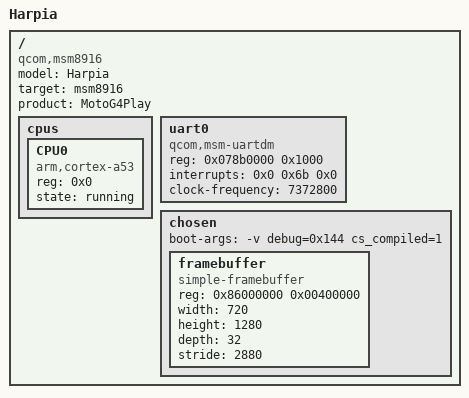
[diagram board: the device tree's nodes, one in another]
/ {
    model = "Harpia";
    target = "msm8916";
    product = "MotoG4Play";
    compatible = "qcom,msm8916";
    #adress-cells = <1>;
    #size-cells = <1>;

    cpus {
        #adress-cells = <1>;
        #size-cells = <0>;

        CPU0 {
            device_type = "cpu";
            compatible = "arm,cortex-a53";
            reg = <0x0>;
            state = "running";
        };
    };

    uart0 {
        device_type = "uart";
        compatible = "qcom,msm-uartdm";
        reg = <0x078b0000 0x1000>;
        interrupts = <0x0 0x6b 0x0>;
        clock-frequency = <7372800>;
    };

    chosen {
        boot-args = "-v debug=0x144 cs_compiled=1";

        framebuffer {
            device_type = "display";
            compatible = "simple-framebuffer";
            reg = <0x86000000 0x00400000>;
            width = <720>;
            height = <1280>;
            depth = <32>;
            stride = <2880>;
        };
    };
};
